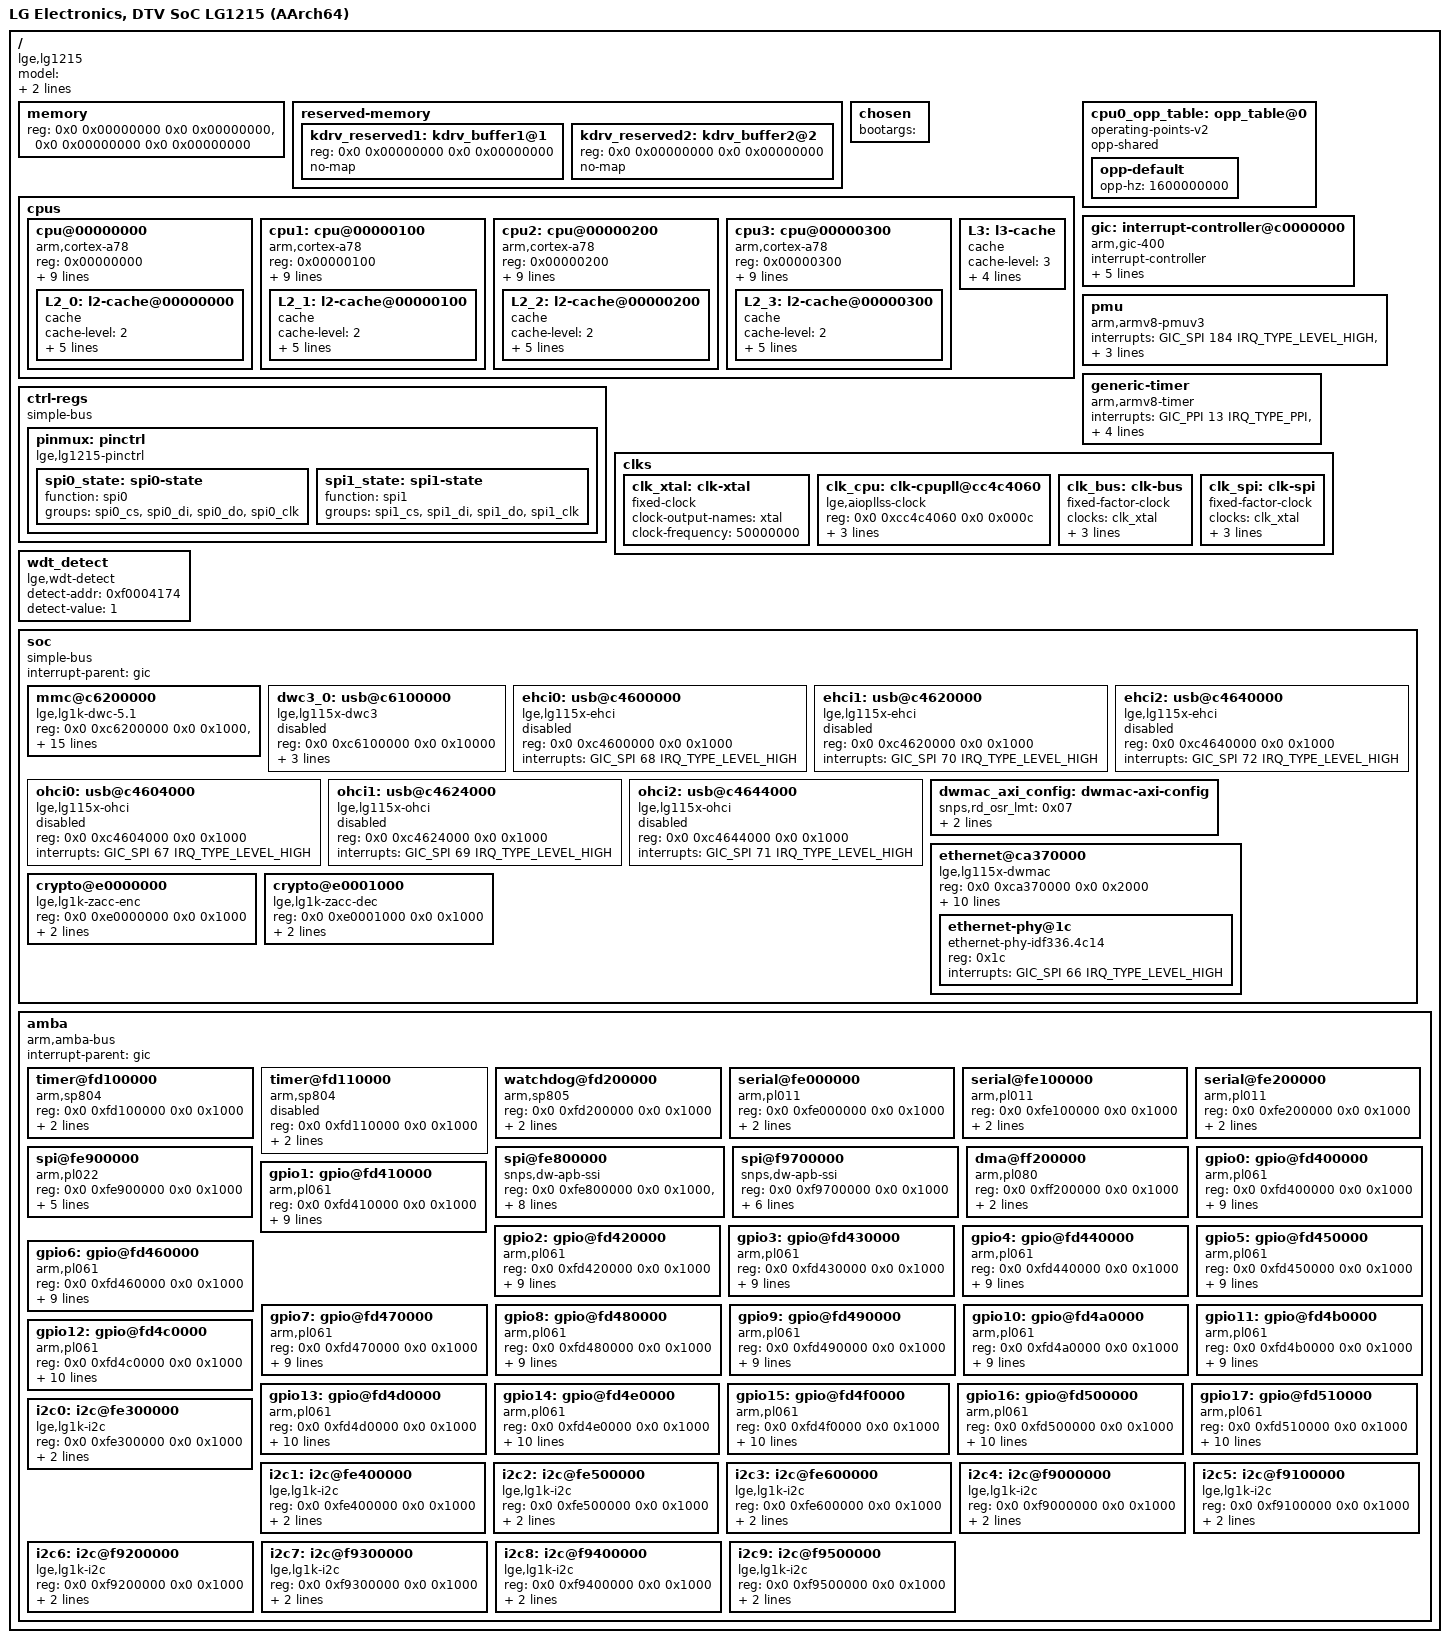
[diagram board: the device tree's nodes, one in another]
/dts-v1/;

/* reserve zero-page for CPU-PM operations */
/memreserve/ 0x00000000 0x00001000;

#include <dt-bindings/gpio/gpio.h>
#include <dt-bindings/interrupt-controller/arm-gic.h>

#define IRQ_TYPE_PPI	(GIC_CPU_MASK_RAW(0x0f) | IRQ_TYPE_LEVEL_LOW)

/ {
	model = "LG Electronics, DTV SoC LG1215 (AArch64)";	/* AKA O26 */
	compatible = "lge,lg1215", "lge,lg1k";
	interrupt-parent = <&gic>;

	#address-cells = <2>;
	#size-cells = <2>;

	memory {
		#address-cells = <2>;
		#size-cells = <2>;
		ranges;

		device_type = "memory";
		/* Filled in by lxboot */
		reg = <0x0 0x00000000 0x0 0x00000000>,
		      <0x0 0x00000000 0x0 0x00000000>;
	};

	reserved-memory {
		#address-cells = <2>;
		#size-cells = <2>;
		ranges;

		/* Filled in by lxboot */
		kdrv_reserved1: kdrv_buffer1@1 {
			reg = <0x0 0x00000000 0x0 0x00000000>;
			no-map;
		};
		kdrv_reserved2: kdrv_buffer2@2 {
			reg = <0x0 0x00000000 0x0 0x00000000>;
			no-map;
		};
	};

	chosen {
		bootargs = "";
	};

	cpus {
		#address-cells = <1>;
		#size-cells = <0>;

		cpu@00000000 {
			device_type = "cpu";
			compatible = "arm,cortex-a78";
			reg = <0x00000000>;
			clocks = <&clk_cpu>;
			clock-names = "cpuclk";
			operating-points-v2 = <&cpu0_opp_table>;
			d-cache-line-size = <64>;
			d-cache-sets = <256>;
			d-cache-size = <0x00010000>;
			i-cache-line-size = <64>;
			i-cache-sets = <256>;
			i-cache-size = <0x00010000>;
			next-level-cache = <&L2_0>;
			L2_0: l2-cache@00000000 {
				compatible = "cache";
				cache-level = <2>;
				cache-line-size = <64>;
				cache-sets = <512>;
				cache-size = <0x00040000>;
				cache-unified;
				next-level-cache = <&L3>;
			};
		};
		cpu1: cpu@00000100 {
			device_type = "cpu";
			compatible = "arm,cortex-a78";
			reg = <0x00000100>;
			clocks = <&clk_cpu>;
			clock-names = "cpuclk";
			operating-points-v2 = <&cpu0_opp_table>;
			d-cache-line-size = <64>;
			d-cache-sets = <256>;
			d-cache-size = <0x00010000>;
			i-cache-line-size = <64>;
			i-cache-sets = <256>;
			i-cache-size = <0x00010000>;
			next-level-cache = <&L2_1>;
			L2_1: l2-cache@00000100 {
				compatible = "cache";
				cache-level = <2>;
				cache-line-size = <64>;
				cache-sets = <512>;
				cache-size = <0x00040000>;
				cache-unified;
				next-level-cache = <&L3>;
			};
		};
		cpu2: cpu@00000200 {
			device_type = "cpu";
			compatible = "arm,cortex-a78";
			reg = <0x00000200>;
			clocks = <&clk_cpu>;
			clock-names = "cpuclk";
			operating-points-v2 = <&cpu0_opp_table>;
			d-cache-line-size = <64>;
			d-cache-sets = <256>;
			d-cache-size = <0x00010000>;
			i-cache-line-size = <64>;
			i-cache-sets = <256>;
			i-cache-size = <0x00010000>;
			next-level-cache = <&L2_2>;
			L2_2: l2-cache@00000200 {
				compatible = "cache";
				cache-level = <2>;
				cache-line-size = <64>;
				cache-sets = <512>;
				cache-size = <0x00040000>;
				cache-unified;
				next-level-cache = <&L3>;
			};
		};
		cpu3: cpu@00000300 {
			device_type = "cpu";
			compatible = "arm,cortex-a78";
			reg = <0x00000300>;
			clocks = <&clk_cpu>;
			clock-names = "cpuclk";
			operating-points-v2 = <&cpu0_opp_table>;
			d-cache-line-size = <64>;
			d-cache-sets = <256>;
			d-cache-size = <0x00010000>;
			i-cache-line-size = <64>;
			i-cache-sets = <256>;
			i-cache-size = <0x00010000>;
			next-level-cache = <&L2_3>;
			L2_3: l2-cache@00000300 {
				compatible = "cache";
				cache-level = <2>;
				cache-line-size = <64>;
				cache-sets = <512>;
				cache-size = <0x00040000>;
				cache-unified;
				next-level-cache = <&L3>;
			};
		};
		L3: l3-cache {
			compatible = "cache";
			cache-level = <3>;
			cache-line-size = <64>;
			cache-sets = <512>;
			cache-size = <0x00100000>;
			cache-unified;
		};
	};

	cpu0_opp_table: opp_table@0 {
		compatible = "operating-points-v2";
		opp-shared;

		opp-default {
			opp-hz = /bits/ 64 <1600000000>;
		};
	};

	gic: interrupt-controller@c0000000 {
		#address-cells = <2>;
		#size-cells = <2>;
		ranges;

		compatible = "arm,gic-400";
		interrupt-controller;
		reg = <0x0 0xc0001000 0x0 0x1000>,	/* GICD */
		      <0x0 0xc0002000 0x0 0x2000>,	/* GICC */
		      <0x0 0xc0004000 0x0 0x2000>,	/* GICH */
		      <0x0 0xc0006000 0x0 0x2000>;	/* GICV */
		interrupts = <GIC_PPI 9 IRQ_TYPE_PPI>;	/* VMI */

		#interrupt-cells = <3>;
	};

	pmu {
		compatible = "arm,armv8-pmuv3";
		interrupts = <GIC_SPI 184 IRQ_TYPE_LEVEL_HIGH>,
			     <GIC_SPI 185 IRQ_TYPE_LEVEL_HIGH>,
			     <GIC_SPI 186 IRQ_TYPE_LEVEL_HIGH>,
			     <GIC_SPI 187 IRQ_TYPE_LEVEL_HIGH>;
	};

	generic-timer {
		compatible = "arm,armv8-timer";
		interrupts = <GIC_PPI 13 IRQ_TYPE_PPI>,	/* SP */
			     <GIC_PPI 14 IRQ_TYPE_PPI>,	/* NSP */
			     <GIC_PPI 11 IRQ_TYPE_PPI>,	/* V */
			     <GIC_PPI 10 IRQ_TYPE_PPI>;	/* H */
		clock-frequency = <50000000>;
	};

	ctrl-regs {
		compatible = "simple-bus";

		pinmux: pinctrl {
			compatible = "lge,lg1215-pinctrl";

			spi0_state: spi0-state {
				function = "spi0";
				groups = "spi0_cs","spi0_di","spi0_do","spi0_clk";
			};
			spi1_state: spi1-state {
				function = "spi1";
				groups = "spi1_cs","spi1_di","spi1_do","spi1_clk";
			};
		};
	};

	clks {
		#address-cells = <2>;
		#size-cells = <2>;
		ranges;

		clk_xtal: clk-xtal {
			compatible = "fixed-clock";
			clock-output-names = "xtal";
			clock-frequency = <50000000>;

			#clock-cells = <0>;
		};
		clk_cpu: clk-cpupll@cc4c4060 {
			compatible = "lge,aiopllss-clock";
			reg = <0x0 0xcc4c4060 0x0 0x000c>;
			clocks = <&clk_xtal>;
			clock-names = "xtal";
			clock-output-names = "cpuclk";
			param = <0 24 6 0 16 6 0 12 4 1 0 7>;

			#clock-cells = <0>;
		};
		clk_bus: clk-bus {
			compatible = "fixed-factor-clock";
			clocks = <&clk_xtal>;
			clock-names = "xtal";
			clock-output-names = "busclk";
			clock-div = <1>;
			clock-mult = <4>;

			#clock-cells = <0>;
		};
		clk_spi: clk-spi {
			compatible = "fixed-factor-clock";
			clocks = <&clk_xtal>;
			clock-names = "xtal";
			clock-output-names = "spiclk";
			clock-div = <1>;
			clock-mult = <8>;

			#clock-cells = <0>;
		};
	};

	/* TODO: CHECK ADDRESS */
	wdt_detect {
		compatible = "lge,wdt-detect";
		detect-addr = <0xf0004174>;
		detect-value = <1>;
	};

	soc {
		compatible = "simple-bus";

		#address-cells = <2>;
		#size-cells = <2>;
		ranges;

		interrupt-parent = <&gic>;

		mmc@c6200000 {
			compatible = "lge,lg1k-dwc-5.1";
			reg = <0x0 0xc6200000 0x0 0x1000>,
			      <0x0 0xc6202000 0x0 0x1000>;
			interrupts = <GIC_SPI 64 IRQ_TYPE_LEVEL_HIGH>;
			clock-frequency = <200000000>;
			/* Filled in by lxboot */
			reset-reg = <0xc621000c>;
			reset-value = <0xf>;
			intap-delay = <0x0>;
			outtap-delay = <0x0>;
			device-ds = <0>;
			host-ds = <0>;
			op-mode = <0>;
			strobe = <0x0>;
			hw-clockgating = <0x0>;
			hw-autotune = <0x0>;
			cqe-enable = <0x0>;
			internal-pullup = <0x1>;
		};

		dwc3_0: usb@c6100000 { // bt-wifi
			compatible = "lge,lg115x-dwc3", "snps,dwc3";
			reg = <0x0 0xc6100000 0x0 0x10000>;
			interrupts = <GIC_SPI 73 IRQ_TYPE_LEVEL_HIGH>;
			status = "skip";

			clocks = <&clk_bus>, <&clk_bus>, <&clk_bus>;
			clock-names = "ref", "bus_early", "suspend";
			dr_mode = "host";
		};
		ehci0: usb@c4600000 { // user-port1
			compatible = "lge,lg115x-ehci", "generic-ehci";
			reg = <0x0 0xc4600000 0x0 0x1000>;
			interrupts = <GIC_SPI 68 IRQ_TYPE_LEVEL_HIGH>;
			status = "skip";
		};
		ehci1: usb@c4620000 { // user-port2
			compatible = "lge,lg115x-ehci", "generic-ehci";
			reg = <0x0 0xc4620000 0x0 0x1000>;
			interrupts = <GIC_SPI 70 IRQ_TYPE_LEVEL_HIGH>;
			status = "skip";
		};
		ehci2: usb@c4640000 { // user-port3
			compatible = "lge,lg115x-ehci", "generic-ehci";
			reg = <0x0 0xc4640000 0x0 0x1000>;
			interrupts = <GIC_SPI 72 IRQ_TYPE_LEVEL_HIGH>;
			status = "skip";
		};
		ohci0: usb@c4604000 { // user-port1
			compatible = "lge,lg115x-ohci", "generic-ohci";
			reg = <0x0 0xc4604000 0x0 0x1000>;
			interrupts = <GIC_SPI 67 IRQ_TYPE_LEVEL_HIGH>;
			status = "skip";
		};
		ohci1: usb@c4624000 { // user-port2
			compatible = "lge,lg115x-ohci", "generic-ohci";
			reg = <0x0 0xc4624000 0x0 0x1000>;
			interrupts = <GIC_SPI 69 IRQ_TYPE_LEVEL_HIGH>;
			status = "skip";
		};
		ohci2: usb@c4644000 { // user-port3
			compatible = "lge,lg115x-ohci", "generic-ohci";
			reg = <0x0 0xc4644000 0x0 0x1000>;
			interrupts = <GIC_SPI 71 IRQ_TYPE_LEVEL_HIGH>;
			status = "skip";
		};

		dwmac_axi_config: dwmac-axi-config {
			snps,rd_osr_lmt = <0x07>;
			snps,wr_osr_lmt = <0x07>;
			snps,blen = <0 0 16 0 0 0 0>;
		};
		ethernet@ca370000 {
			compatible = "lge,lg115x-dwmac", "snps,dwmac";
			reg = <0x0 0xca370000 0x0 0x2000>;
			interrupts = <GIC_SPI 65 IRQ_TYPE_LEVEL_HIGH>;
			interrupt-names = "macirq";
			clocks = <&clk_bus>, <&clk_bus>;
			clock-names = "stmmaceth", "pclk";
			max-frame-size = <1500>;
			phy-mode = "mii";
			snps,pbl = <2>;
			snps,fixed-burst;
			snps,multicast-filter-bins = <64>;
			snps,perfect-filter-entries = <32>;
			snps,axi-config = <&dwmac_axi_config>;
			/* Filled in by lxboot */
			mac-address = [ 00 00 00 00 00 00 ];

			#address-cells = <1>;
			#size-cells = <0>;

			ethernet-phy@1c {
				compatible = "ethernet-phy-idf336.4c14";
				reg = <0x1c>;
				interrupts = <GIC_SPI 66 IRQ_TYPE_LEVEL_HIGH>;
			};
		};

		crypto@e0000000 {
			compatible = "lge,lg1k-zacc-enc";
			reg = <0x0 0xe0000000 0x0 0x1000>;
			interrupts = <GIC_SPI 42 IRQ_TYPE_LEVEL_HIGH>;
			alignments = <0xfffff000>, <0xfffff000>;
		};
		crypto@e0001000 {
			compatible = "lge,lg1k-zacc-dec";
			reg = <0x0 0xe0001000 0x0 0x1000>;
			interrupts = <GIC_SPI 43 IRQ_TYPE_LEVEL_HIGH>;
			alignments = <0xfffff000>, <0xfffffff0>;
		};
	};

	amba {
		compatible = "arm,amba-bus";

		#address-cells = <2>;
		#size-cells = <2>;
		ranges;

		interrupt-parent = <&gic>;

		timer@fd100000 {
			compatible = "arm,sp804";
			reg = <0x0 0xfd100000 0x0 0x1000>;
			interrupts = <GIC_SPI 6 IRQ_TYPE_LEVEL_HIGH>;
			clocks = <&clk_bus>;
			clock-names = "apb_pclk";
		};
		timer@fd110000 {
			compatible = "arm,sp804";
			reg = <0x0 0xfd110000 0x0 0x1000>;
			interrupts = <GIC_SPI 38 IRQ_TYPE_LEVEL_HIGH>;
			clocks = <&clk_bus>;
			clock-names = "apb_pclk";
			status = "disabled";
		};
		watchdog@fd200000 {
			compatible = "arm,sp805", "arm,primecell";
			reg = <0x0 0xfd200000 0x0 0x1000>;
			interrupts = <GIC_SPI 7 IRQ_TYPE_LEVEL_HIGH>;
			clocks = <&clk_bus>;
			clock-names = "apb_pclk";
		};
		serial@fe000000 {
			compatible = "arm,pl011", "arm,primecell";
			reg = <0x0 0xfe000000 0x0 0x1000>;
			interrupts = <GIC_SPI 0 IRQ_TYPE_LEVEL_HIGH>;
			clocks = <&clk_bus>;
			clock-names = "apb_pclk";
		};
		serial@fe100000 {
			compatible = "arm,pl011", "arm,primecell";
			reg = <0x0 0xfe100000 0x0 0x1000>;
			interrupts = <GIC_SPI 1 IRQ_TYPE_LEVEL_HIGH>;
			clocks = <&clk_bus>;
			clock-names = "apb_pclk";
		};
		serial@fe200000 {
			compatible = "arm,pl011", "arm,primecell";
			reg = <0x0 0xfe200000 0x0 0x1000>;
			interrupts = <GIC_SPI 2 IRQ_TYPE_LEVEL_HIGH>;
			clocks = <&clk_bus>;
			clock-names = "apb_pclk";
		};
		spi@fe800000 {
			compatible = "snps,dw-apb-ssi";
			reg = <0x0 0xfe800000 0x0 0x1000>,
				<0x0 0xcc973000 0x0 0x0004>;
			interrupts = <GIC_SPI 3 IRQ_TYPE_LEVEL_HIGH>;
			clocks = <&clk_spi>;
			clock-names = "spi_pclk";
			pinctrl-names = "default";
			pinctrl-0 = <&spi0_state>;
			num-cs = <1>;
			bus-num = <0>;
			strength = <0x003C00F0 0x00200080>;
			rx-dly = <17>;
		};
		spi@fe900000 {
			compatible = "arm,pl022", "arm,primecell";
			reg = <0x0 0xfe900000 0x0 0x1000>;
			interrupts = <GIC_SPI 4 IRQ_TYPE_LEVEL_HIGH>;
			clocks = <&clk_bus>;
			clock-names = "apb_pclk";
			pinctrl-names = "default";
			pinctrl-0 = <&spi1_state>;
			num-cs = <1>;
			bus-num = <1>;
		};
		spi@f9700000 {
			compatible = "snps,dw-apb-ssi";
			reg = <0x0 0xf9700000 0x0 0x1000>;
			interrupts = <GIC_SPI 46 IRQ_TYPE_LEVEL_HIGH>;
			clocks = <&clk_spi>;
			clock-names = "spi_pclk";
			pinctrl-names = "default";
			num-cs = <1>;
			bus-num = <2>;
			rx-dly = <17>;
			cs-gpios = <&gpio10 4 GPIO_ACTIVE_LOW>;
		};
		dma@ff200000 {
			compatible = "arm,pl080", "arm,primecell";
			reg = <0x0 0xff200000 0x0 0x1000>;
			interrupts = <GIC_SPI 36 IRQ_TYPE_LEVEL_HIGH>;
			clocks = <&clk_bus>;
			clock-names = "apb_pclk";
		};
		gpio0: gpio@fd400000 {
			compatible = "arm,pl061", "arm,primecell";
			reg = <0x0 0xfd400000 0x0 0x1000>;
			interrupts = <GIC_SPI 8 IRQ_TYPE_LEVEL_HIGH>;
			clocks = <&clk_bus>;
			clock-names = "apb_pclk";
			gpio-controller;
			interrupt-controller;
			gpio-base = <0x00>;
			gpio-ranges = <&pinmux 0 0 1 &pinmux 1 1 1
			               &pinmux 2 2 1 &pinmux 3 3 1
			               &pinmux 4 4 1 &pinmux 5 5 1
			               &pinmux 6 6 1 &pinmux 7 7 1>;
			skip-resume = /bits/ 8 <0x00>;

			#gpio-cells = <2>;
			#interrupt-cells = <2>;
		};
		gpio1: gpio@fd410000 {
			compatible = "arm,pl061", "arm,primecell";
			reg = <0x0 0xfd410000 0x0 0x1000>;
			interrupts = <GIC_SPI 9 IRQ_TYPE_LEVEL_HIGH>;
			clocks = <&clk_bus>;
			clock-names = "apb_pclk";
			gpio-controller;
			interrupt-controller;
			gpio-base = <0x08>;
			gpio-ranges = <&pinmux 0 8 1 &pinmux 1 9 1
			               &pinmux 2 10 1 &pinmux 3 11 1
			               &pinmux 4 12 1 &pinmux 5 13 1
			               &pinmux 6 14 1 &pinmux 7 15 1>;
			skip-resume = /bits/ 8 <0x00>;

			#gpio-cells = <2>;
			#interrupt-cells = <2>;
		};
		gpio2: gpio@fd420000 {
			compatible = "arm,pl061", "arm,primecell";
			reg = <0x0 0xfd420000 0x0 0x1000>;
			interrupts = <GIC_SPI 10 IRQ_TYPE_LEVEL_HIGH>;
			clocks = <&clk_bus>;
			clock-names = "apb_pclk";
			gpio-controller;
			interrupt-controller;
			gpio-base = <0x10>;
			gpio-ranges = <&pinmux 0 16 1 &pinmux 1 17 1
			               &pinmux 2 18 1 &pinmux 3 19 1
			               &pinmux 4 20 1 &pinmux 5 21 1
			               &pinmux 6 22 1 &pinmux 7 23 1>;
			skip-resume = /bits/ 8 <0x00>;

			#gpio-cells = <2>;
			#interrupt-cells = <2>;
		};
		gpio3: gpio@fd430000 {
			compatible = "arm,pl061", "arm,primecell";
			reg = <0x0 0xfd430000 0x0 0x1000>;
			interrupts = <GIC_SPI 11 IRQ_TYPE_LEVEL_HIGH>;
			clocks = <&clk_bus>;
			clock-names = "apb_pclk";
			gpio-controller;
			interrupt-controller;
			gpio-base = <0x18>;
			gpio-ranges = <&pinmux 0 24 1 &pinmux 1 25 1
			               &pinmux 2 26 1 &pinmux 3 27 1
			               &pinmux 4 28 1 &pinmux 5 29 1
			               &pinmux 6 30 1 &pinmux 7 31 1>;
			skip-resume = /bits/ 8 <0x00>;

			#gpio-cells = <2>;
			#interrupt-cells = <2>;
		};
		gpio4: gpio@fd440000 {
			compatible = "arm,pl061", "arm,primecell";
			reg = <0x0 0xfd440000 0x0 0x1000>;
			interrupts = <GIC_SPI 12 IRQ_TYPE_LEVEL_HIGH>;
			clocks = <&clk_bus>;
			clock-names = "apb_pclk";
			gpio-controller;
			interrupt-controller;
			gpio-base = <0x20>;
			gpio-ranges = <&pinmux 0 32 1 &pinmux 1 33 1
			               &pinmux 2 34 1 &pinmux 3 35 1
			               &pinmux 4 36 1 &pinmux 5 37 1
			               &pinmux 6 38 1 &pinmux 7 39 1>;
			skip-resume = /bits/ 8 <0x00>;

			#gpio-cells = <2>;
			#interrupt-cells = <2>;
		};
		gpio5: gpio@fd450000 {
			compatible = "arm,pl061", "arm,primecell";
			reg = <0x0 0xfd450000 0x0 0x1000>;
			interrupts = <GIC_SPI 13 IRQ_TYPE_LEVEL_HIGH>;
			clocks = <&clk_bus>;
			clock-names = "apb_pclk";
			gpio-controller;
			interrupt-controller;
			gpio-base = <0x28>;
			gpio-ranges = <&pinmux 0 40 1 &pinmux 1 41 1
			               &pinmux 2 42 1 &pinmux 3 43 1
			               &pinmux 4 44 1 &pinmux 5 45 1
			               &pinmux 6 46 1 &pinmux 7 47 1>;
			skip-resume = /bits/ 8 <0x00>;

			#gpio-cells = <2>;
			#interrupt-cells = <2>;
		};
		gpio6: gpio@fd460000 {
			compatible = "arm,pl061", "arm,primecell";
			reg = <0x0 0xfd460000 0x0 0x1000>;
			interrupts = <GIC_SPI 14 IRQ_TYPE_LEVEL_HIGH>;
			clocks = <&clk_bus>;
			clock-names = "apb_pclk";
			gpio-controller;
			interrupt-controller;
			gpio-base = <0x30>;
			gpio-ranges = <&pinmux 0 48 1 &pinmux 1 49 1
			               &pinmux 2 50 1 &pinmux 3 51 1
			               &pinmux 4 52 1 &pinmux 5 53 1
			               &pinmux 6 54 1 &pinmux 7 55 1>;
			skip-resume = /bits/ 8 <0x00>;

			#gpio-cells = <2>;
			#interrupt-cells = <2>;
		};
		gpio7: gpio@fd470000 {
			compatible = "arm,pl061", "arm,primecell";
			reg = <0x0 0xfd470000 0x0 0x1000>;
			interrupts = <GIC_SPI 15 IRQ_TYPE_LEVEL_HIGH>;
			clocks = <&clk_bus>;
			clock-names = "apb_pclk";
			gpio-controller;
			interrupt-controller;
			gpio-base = <0x38>;
			gpio-ranges = <&pinmux 0 56 1 &pinmux 1 57 1
			               &pinmux 2 58 1 &pinmux 3 59 1
			               &pinmux 4 60 1 &pinmux 5 61 1
			               &pinmux 6 62 1 &pinmux 7 63 1>;
			skip-resume = /bits/ 8 <0x00>;

			#gpio-cells = <2>;
			#interrupt-cells = <2>;
		};
		gpio8: gpio@fd480000 {
			compatible = "arm,pl061", "arm,primecell";
			reg = <0x0 0xfd480000 0x0 0x1000>;
			interrupts = <GIC_SPI 16 IRQ_TYPE_LEVEL_HIGH>;
			clocks = <&clk_bus>;
			clock-names = "apb_pclk";
			gpio-controller;
			interrupt-controller;
			gpio-base = <0x40>;
			gpio-ranges = <&pinmux 0 64 1 &pinmux 1 65 1
			               &pinmux 2 66 1 &pinmux 3 67 1
			               &pinmux 4 68 1 &pinmux 5 69 1
			               &pinmux 6 70 1 &pinmux 7 71 1>;
			skip-resume = /bits/ 8 <0x00>;

			#gpio-cells = <2>;
			#interrupt-cells = <2>;
		};
		gpio9: gpio@fd490000 {
			compatible = "arm,pl061", "arm,primecell";
			reg = <0x0 0xfd490000 0x0 0x1000>;
			interrupts = <GIC_SPI 17 IRQ_TYPE_LEVEL_HIGH>;
			clocks = <&clk_bus>;
			clock-names = "apb_pclk";
			gpio-controller;
			interrupt-controller;
			gpio-base = <0x48>;
			gpio-ranges = <&pinmux 0 72 1 &pinmux 1 73 1
			               &pinmux 2 74 1 &pinmux 3 75 1
			               &pinmux 4 76 1 &pinmux 5 77 1
			               &pinmux 6 78 1 &pinmux 7 79 1>;
			skip-resume = /bits/ 8 <0x00>;

			#gpio-cells = <2>;
			#interrupt-cells = <2>;
		};
		gpio10: gpio@fd4a0000 {
			compatible = "arm,pl061", "arm,primecell";
			reg = <0x0 0xfd4a0000 0x0 0x1000>;
			interrupts = <GIC_SPI 18 IRQ_TYPE_LEVEL_HIGH>;
			clocks = <&clk_bus>;
			clock-names = "apb_pclk";
			gpio-controller;
			interrupt-controller;
			gpio-base = <0x50>;
			gpio-ranges = <&pinmux 0 80 1 &pinmux 1 81 1
			               &pinmux 2 82 1 &pinmux 3 83 1
			               &pinmux 4 84 1 &pinmux 5 85 1
			               &pinmux 6 86 1 &pinmux 7 87 1>;
			skip-resume = /bits/ 8 <0x00>;

			#gpio-cells = <2>;
			#interrupt-cells = <2>;
		};
		gpio11: gpio@fd4b0000 {
			compatible = "arm,pl061", "arm,primecell";
			reg = <0x0 0xfd4b0000 0x0 0x1000>;
			interrupts = <GIC_SPI 19 IRQ_TYPE_LEVEL_HIGH>;
			clocks = <&clk_bus>;
			clock-names = "apb_pclk";
			gpio-controller;
			interrupt-controller;
			gpio-base = <0x58>;
			gpio-ranges = <&pinmux 0 88 1 &pinmux 1 89 1
			               &pinmux 2 90 1 &pinmux 3 91 1
			               &pinmux 4 92 1 &pinmux 5 93 1
			               &pinmux 6 94 1 &pinmux 7 95 1>;
			skip-resume = /bits/ 8 <0x00>;

			#gpio-cells = <2>;
			#interrupt-cells = <2>;
		};
		gpio12: gpio@fd4c0000 {
			compatible = "arm,pl061", "arm,primecell";
			reg = <0x0 0xfd4c0000 0x0 0x1000>;
			interrupts = <GIC_SPI 20 IRQ_TYPE_LEVEL_HIGH>;
			clocks = <&clk_bus>;
			clock-names = "apb_pclk";
			gpio-controller;
			interrupt-controller;
			gpio-base = <0x60>;
			gpio-ranges = <&pinmux 0 96 1 &pinmux 1 97 1
			               &pinmux 2 98 1 &pinmux 3 99 1
			               &pinmux 4 100 1 &pinmux 5 101 1
			               &pinmux 6 102 1 &pinmux 7 103 1>;
			skip-resume = /bits/ 8 <0x00>;

			#gpio-cells = <2>;
			#interrupt-cells = <2>;
		};
		gpio13: gpio@fd4d0000 {
			compatible = "arm,pl061", "arm,primecell";
			reg = <0x0 0xfd4d0000 0x0 0x1000>;
			interrupts = <GIC_SPI 21 IRQ_TYPE_LEVEL_HIGH>;
			clocks = <&clk_bus>;
			clock-names = "apb_pclk";
			gpio-controller;
			interrupt-controller;
			gpio-base = <0x68>;
			gpio-ranges = <&pinmux 0 104 1 &pinmux 1 105 1
			               &pinmux 2 106 1 &pinmux 3 107 1
			               &pinmux 4 108 1 &pinmux 5 109 1
			               &pinmux 6 110 1 &pinmux 7 111 1>;
			skip-resume = /bits/ 8 <0x00>;

			#gpio-cells = <2>;
			#interrupt-cells = <2>;
		};
		gpio14: gpio@fd4e0000 {
			compatible = "arm,pl061", "arm,primecell";
			reg = <0x0 0xfd4e0000 0x0 0x1000>;
			interrupts = <GIC_SPI 22 IRQ_TYPE_LEVEL_HIGH>;
			clocks = <&clk_bus>;
			clock-names = "apb_pclk";
			gpio-controller;
			interrupt-controller;
			gpio-base = <0x70>;
			gpio-ranges = <&pinmux 0 112 1 &pinmux 1 113 1
			               &pinmux 2 114 1 &pinmux 3 115 1
			               &pinmux 4 116 1 &pinmux 5 117 1
			               &pinmux 6 118 1 &pinmux 7 119 1>;
			skip-resume = /bits/ 8 <0x00>;

			#gpio-cells = <2>;
			#interrupt-cells = <2>;
		};
		gpio15: gpio@fd4f0000 {
			compatible = "arm,pl061", "arm,primecell";
			reg = <0x0 0xfd4f0000 0x0 0x1000>;
			interrupts = <GIC_SPI 23 IRQ_TYPE_LEVEL_HIGH>;
			clocks = <&clk_bus>;
			clock-names = "apb_pclk";
			gpio-controller;
			interrupt-controller;
			gpio-base = <0x78>;
			gpio-ranges = <&pinmux 0 120 1 &pinmux 1 121 1
			               &pinmux 2 122 1 &pinmux 3 123 1
			               &pinmux 4 124 1 &pinmux 5 125 1
			               &pinmux 6 126 1 &pinmux 7 127 1>;
			skip-resume = /bits/ 8 <0x00>;

			#gpio-cells = <2>;
			#interrupt-cells = <2>;
		};
		gpio16: gpio@fd500000 {
			compatible = "arm,pl061", "arm,primecell";
			reg = <0x0 0xfd500000 0x0 0x1000>;
			interrupts = <GIC_SPI 24 IRQ_TYPE_LEVEL_HIGH>;
			clocks = <&clk_bus>;
			clock-names = "apb_pclk";
			gpio-controller;
			interrupt-controller;
			gpio-base = <0x80>;
			gpio-ranges = <&pinmux 0 128 1 &pinmux 1 129 1
			               &pinmux 2 130 1 &pinmux 3 131 1
			               &pinmux 4 132 1 &pinmux 5 133 1
			               &pinmux 6 134 1 &pinmux 7 135 1>;
			skip-resume = /bits/ 8 <0x00>;

			#gpio-cells = <2>;
			#interrupt-cells = <2>;
		};
		gpio17: gpio@fd510000 {
			compatible = "arm,pl061", "arm,primecell";
			reg = <0x0 0xfd510000 0x0 0x1000>;
			interrupts = <GIC_SPI 25 IRQ_TYPE_LEVEL_HIGH>;
			clocks = <&clk_bus>;
			clock-names = "apb_pclk";
			gpio-controller;
			interrupt-controller;
			gpio-base = <0x88>;
			gpio-ranges = <&pinmux 0 136 1 &pinmux 1 137 1
			               &pinmux 2 138 1 &pinmux 3 139 1
			               &pinmux 4 140 1 &pinmux 5 141 1
			               &pinmux 6 142 1 &pinmux 7 143 1>;
			skip-resume = /bits/ 8 <0x00>;

			#gpio-cells = <2>;
			#interrupt-cells = <2>;
		};
		i2c0: i2c@fe300000 {
			compatible = "lge,lg1k-i2c";
			reg = <0x0 0xfe300000 0x0 0x1000>;
			interrupts = <GIC_SPI 26 IRQ_TYPE_LEVEL_HIGH>;
			clocks = <&clk_bus>;
			clock-names = "apb_pclk";

			#address-cells = <1>;
			#size-cells = <0>;
		};
		i2c1: i2c@fe400000 {
			compatible = "lge,lg1k-i2c";
			reg = <0x0 0xfe400000 0x0 0x1000>;
			interrupts = <GIC_SPI 27 IRQ_TYPE_LEVEL_HIGH>;
			clocks = <&clk_bus>;
			clock-names = "apb_pclk";

			#address-cells = <1>;
			#size-cells = <0>;
		};
		i2c2: i2c@fe500000 {
			compatible = "lge,lg1k-i2c";
			reg = <0x0 0xfe500000 0x0 0x1000>;
			interrupts = <GIC_SPI 28 IRQ_TYPE_LEVEL_HIGH>;
			clocks = <&clk_bus>;
			clock-names = "apb_pclk";

			#address-cells = <1>;
			#size-cells = <0>;
		};
		i2c3: i2c@fe600000 {
			compatible = "lge,lg1k-i2c";
			reg = <0x0 0xfe600000 0x0 0x1000>;
			interrupts = <GIC_SPI 29 IRQ_TYPE_LEVEL_HIGH>;
			clocks = <&clk_bus>;
			clock-names = "apb_pclk";

			#address-cells = <1>;
			#size-cells = <0>;
		};
		i2c4: i2c@f9000000 {
			compatible = "lge,lg1k-i2c";
			reg = <0x0 0xf9000000 0x0 0x1000>;
			interrupts = <GIC_SPI 30 IRQ_TYPE_LEVEL_HIGH>;
			clocks = <&clk_bus>;
			clock-names = "apb_pclk";

			#address-cells = <1>;
			#size-cells = <0>;
		};
		i2c5: i2c@f9100000 {
			compatible = "lge,lg1k-i2c";
			reg = <0x0 0xf9100000 0x0 0x1000>;
			interrupts = <GIC_SPI 31 IRQ_TYPE_LEVEL_HIGH>;
			clocks = <&clk_bus>;
			clock-names = "apb_pclk";

			#address-cells = <1>;
			#size-cells = <0>;
		};
		i2c6: i2c@f9200000 {
			compatible = "lge,lg1k-i2c";
			reg = <0x0 0xf9200000 0x0 0x1000>;
			interrupts = <GIC_SPI 32 IRQ_TYPE_LEVEL_HIGH>;
			clocks = <&clk_bus>;
			clock-names = "apb_pclk";

			#address-cells = <1>;
			#size-cells = <0>;
		};
		i2c7: i2c@f9300000 {
			compatible = "lge,lg1k-i2c";
			reg = <0x0 0xf9300000 0x0 0x1000>;
			interrupts = <GIC_SPI 33 IRQ_TYPE_LEVEL_HIGH>;
			clocks = <&clk_bus>;
			clock-names = "apb_pclk";

			#address-cells = <1>;
			#size-cells = <0>;
		};
		i2c8: i2c@f9400000 {
			compatible = "lge,lg1k-i2c";
			reg = <0x0 0xf9400000 0x0 0x1000>;
			interrupts = <GIC_SPI 34 IRQ_TYPE_LEVEL_HIGH>;
			clocks = <&clk_bus>;
			clock-names = "apb_pclk";

			#address-cells = <1>;
			#size-cells = <0>;
		};
		i2c9: i2c@f9500000 {
			compatible = "lge,lg1k-i2c";
			reg = <0x0 0xf9500000 0x0 0x1000>;
			interrupts = <GIC_SPI 35 IRQ_TYPE_LEVEL_HIGH>;
			clocks = <&clk_bus>;
			clock-names = "apb_pclk";

			#address-cells = <1>;
			#size-cells = <0>;
		};
	};
};
